# MIK32 register map
Vendor: Mikron; Series: MIK32; File version: 1.0
Registers are 32-bit, read-write, reset 0x0 unless marked. A register's access mark holds for its fields unless they carry their own. Offsets are from the block's base; [hi:lo] are bit positions; 'fields as' and 'values as' point back to an identical list.

## DMA — Прямой доступ к памяти
Base 0x00040000
0x00 CH1_DST — Регистр адреса назначения канала 1
  [31:0] DST — Адрес назначения. В режиме чтения текущего статуса (Current_valuе=1) возвращает последнюю переданную подзадачу контроллера канала. В случае ошибки записи содержит указатель на текущий адрес мастер-интерфейса
0x04 CH1_SRC — Регистр адреса источника канала 1
  [31:0] SCR — Адрес источника В режиме чтения текущего статуса (Current_valuе=1) возвращает текущую подзадачу контроллера канала. Указатель на адрес блока, который обрабатывается вычисляется как: Current_ch_read_task - 2^READ_BURST_SIZE В случае ошибки записи содержит указатель на текущий адрес мастер-интерфейса, вернувшего HRESP=1
0x08 CH1_LEN — Регистр размера передаваемых данных канала 1
  [31:0] LEN — Количество байт пересылки рассчитывается как LEN +1 В режиме чтения текущего статуса (Current_valuе=1) возвращает счётчик байт подзадач контроллера. Счётчик байт подзадач обновляется только по подзадачам записи. Кол-во байт в блоках, которые удалось записать вычисляется как: If (state==write): LEN - 2^WRITE_BURST_SIZE If (state==read): Current byte len
0x0C CH1_CFG — Регистр управления и конфигурации канала 1
  [27] IRQ_EN — Разрешение формирования пре-рывания по завершении работы канала: 0 – прерывание не формируется; 1 – прерывание формируется
    0=Disable (Прерывание не формируется); 1=Enable (Прерывание формируется)
  [26] WRITE_ACK_EN — Разрешение работы логики с откликом для адресата назначения
    0=Disable (Запрещено); 1=Enable (Разрешено)
  [25] READ_ACK_EN — Разрешение работы логики с откликом для адресата источника
    0=Disable (Запрещено); 1=Enable (Разрешено)
  [24:21] WRITE_REQUEST — Выбор периферийной линии назначения
    0=USART_0 (Линия запросов от USART_0); 1=USART_1 (Линия запросов от USART_1); 2=Crypto (Линия запросов от крипто-блока); 3=SPI_0 (Линия запросов от SPI_0); 4=SPI_1 (Линия запросов от SPI_1); 5=I2C_0 (Линия запросов от I2C_0); 6=I2C_1 (Линия запросов от I2C_1); 7=SPIFI (Линия запросов от SPIFI); 8=Timer32_1 (Линия запросов от Timer32_1); 9=Timer32_2 (Линия запросов от Timer32_2); 10=DAC0 (Линия запросов от DAC0); 11=DAC1 (Линия запросов от DAC1); 12=Timer32_0 (Линия запросов от Timer32_0)
  [20:17] READ_REQUEST — Выбор периферийной линии источника
    values as WRITE_REQUEST
  [16:14] WRITE_BURST_SIZE — Количество байт в пакете. Определяется как 2^write_block_size. Должно быть кратно write_size.
  [13:11] READ_BURST_SIZE — Количество байт в пакете. Определяется как 2^read_block_size. Должно быть кратно read_size.
  [10:9] WRITE_SIZE — Разрядность адреса назначения. Должно быть кратно LEN
    0=Byte (Байт); 1=2Byte (Полуслово); 2=4Byte (Слово); 3=Reserved (Резерв)
  [8:7] READ_SIZE — Разрядность адреса источника. Должно быть кратно data_len
    values as WRITE_SIZE
  [5] READ_INCREMENT — Инкремент адреса источника
    0=No_increment (Нет инкремента); 1=Increment (Есть инкремент)
  [5] WRITE_INCREMENT — Инкремент адреса назначения
    values as READ_INCREMENT
  [4] WRITE_MODE — Режим адреса назначения
    0=Periphery (Принудительная остановка); 1=Memory (Инициализация работы канала)
  [3] READ_MODE — Режим адреса источника
    values as WRITE_MODE
  [2:1] PRIOR — Приоритет канала
    0=Low (Принудительная остановка); 1=Medium (Инициализация работы канала); 2=High (Инициализация работы канала); 3=Very_high (Инициализация работы канала)
  [0] ENABLE — Разрешение работы канала
    0=Stop (Принудительная остановка); 1=Start (Инициализация работы канала)
0x10 CH2_DST — Регистр адреса назначения канала 2
  [31:0] Dst — Адрес назначения. В режиме чтения текущего статуса (Current_valuе=1) возвращает последнюю переданную подзадачу контроллера канала. В случае ошибки записи содержит указатель на текущий адрес мастер-интерфейса
0x14 CH2_SRC — Регистр адреса источника канала 2
  [31:0] Src — Адрес источника В режиме чтения текущего статуса (Current_valuе=1) возвращает текущую подзадачу контроллера канала. Указатель на адрес блока, который обрабатывается вычисляется как: Current_ch_read_task - 2^READ_BURST_SIZE В случае ошибки записи содержит указатель на текущий адрес мастер-интерфейса, вернувшего HRESP=1
0x18 CH2_LEN — Регистр размера передаваемых данных канала 2
  fields as CH1_LEN
0x1C CH2_CFG — Регистр управления и конфигурации канала 2
  [27] IRQ_EN — Разрешение формирования пре-рывания по завершении работы канала: 0 – прерывание не формируется; 1 – прерывание формируется
    values as CH1_CFG.IRQ_EN
  [26] WRITE_ACK_EN — Разрешение работы логики с откликом для адресата назначения
    0=Disable (Запрещено); 1=Enable (Разрешено)
  [25] READ_ACK_EN — Разрешение работы логики с откликом для адресата источника
    0=Disable (Запрещено); 1=Enable (Разрешено)
  [24:21] WRITE_REQUEST — Выбор периферийной линии назначения
    values as CH1_CFG.WRITE_REQUEST
  [20:17] READ_REQUEST — Выбор периферийной линии источника
    values as CH1_CFG.WRITE_REQUEST
  [16:14] WRITE_BURST_SIZE — Количество байт в пакете. Определяется как 2^write_block_size. Должно быть кратно write_size.
  [13:11] READ_BURST_SIZE — Количество байт в пакете. Определяется как 2^read_block_size. Должно быть кратно read_size.
  [10:9] WRITE_SIZE — Разрядность адреса назначения. Должно быть кратно LEN
    0=Byte (Байт); 1=2Byte (Полуслово); 2=4Byte (Слово)
  [8:7] READ_SIZE — Разрядность адреса источника. Должно быть кратно data_len
    0=Byte (Байт); 1=2Byte (Полуслово); 2=4Byte (Слово)
  [5] READ_INCREMENT — Инкремент адреса источника
    values as CH1_CFG.READ_INCREMENT
  [5] WRITE_INCREMENT — Инкремент адреса назначения
    values as CH1_CFG.READ_INCREMENT
  [4] WRITE_MODE — Режим адреса назначения
    values as CH1_CFG.WRITE_MODE
  [3] READ_MODE — Режим адреса источника
    values as CH1_CFG.WRITE_MODE
  [2:1] PRIOR — Приоритет канала
    values as CH1_CFG.PRIOR
  [0] ENABLE — Разрешение работы канала
    values as CH1_CFG.ENABLE
0x20 CH3_DST — Регистр адреса назначения канала 3
  fields as CH2_DST
0x24 CH3_SRC — Регистр адреса источника канала 3
  fields as CH2_SRC
0x28 CH3_LEN — Регистр размера передаваемых данных канала 3
  fields as CH1_LEN
0x2C CH3_CFG — Регистр управления и конфигурации канала 3
  fields as CH2_CFG
0x30 CH4_DST — Регистр адреса назначения канала 4
  fields as CH2_DST
0x34 CH4_SRC — Регистр адреса источника канала 4
  fields as CH2_SRC
0x38 CH4_LEN — Регистр размера передаваемых данных канала 4
  fields as CH1_LEN
0x3C CH4_CFG — Регистр управления и конфигурации канала 4
  [27] IRQ_EN — Разрешение формирования прерывания по завершении работы канала: 0 – прерывание не формируется; 1 – прерывание формируется
    values as CH1_CFG.IRQ_EN
  [26] WRITE_ACK_EN — Разрешение работы логики с откликом для адресата назначения
    0=Disable (Запрещено); 1=Enable (Разрешено)
  [25] READ_ACK_EN — Разрешение работы логики с откликом для адресата источника
    0=Disable (Запрещено); 1=Enable (Разрешено)
  [24:21] WRITE_REQUEST — Выбор периферийной линии назначения
    values as CH1_CFG.WRITE_REQUEST
  [20:17] READ_REQUEST — Выбор периферийной линии источника
    values as CH1_CFG.WRITE_REQUEST
  [16:14] WRITE_BURST_SIZE — Количество байт в пакете. Определяется как 2^write_block_size. Должно быть кратно write_size.
  [13:11] READ_BURST_SIZE — Количество байт в пакете. Определяется как 2^read_block_size. Должно быть кратно read_size.
  [10:9] WRITE_SIZE — Разрядность адреса назначения. Должно быть кратно LEN
    0=Byte (Байт); 1=2Byte (Полуслово); 2=4Byte (Слово)
  [8:7] READ_SIZE — Разрядность адреса источника. Должно быть кратно data_len
    0=Byte (Байт); 1=2Byte (Полуслово); 2=4Byte (Слово)
  [5] READ_INCREMENT — Инкремент адреса источника
    values as CH1_CFG.READ_INCREMENT
  [5] WRITE_INCREMENT — Инкремент адреса назначения
    values as CH1_CFG.READ_INCREMENT
  [4] WRITE_MODE — Режим адреса назначения
    values as CH1_CFG.WRITE_MODE
  [3] READ_MODE — Режим адреса источника
    values as CH1_CFG.WRITE_MODE
  [2:1] PRIOR — Приоритет канала
    values as CH1_CFG.PRIOR
  [0] ENABLE — Разрешение работы канала
    values as CH1_CFG.ENABLE
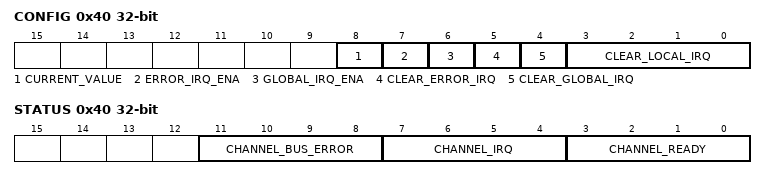
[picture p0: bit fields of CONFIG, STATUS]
0x40 CONFIG wo — Регистр прерываний и настройки контроллера при записи
  [8] CURRENT_VALUE — Разрешение чтения текущего статуса канала
    0=Disable (Разрешено (текущие значения)); 1=Enable (Запрещено (значения при настройке))
  [7] ERROR_IRQ_ENA — Разрешение формирования прерывания при ошибке
    0=Disable (Прерывание запрещено); 1=Enable (Прерывание разрешено)
  [6] GLOBAL_IRQ_ENA — Разрешение формирования глобального прерывания
    values as ERROR_IRQ_ENA
  [5] CLEAR_ERROR_IRQ — Очистка прерывания ошибки: «1» – снятие запроса на прерывание
    1=Reset (снятие запроса на прерывание)
  [4] CLEAR_GLOBAL_IRQ — Очистка глобального прерывания: «1» – снятие запроса на прерывание
    1=Reset (снятие запроса на прерывание)
  [3:0] CLEAR_LOCAL_IRQ — Очистка локального прерывания
    1=Reset (снятие запроса на прерывание)
0x40 STATUS ro — Регистр прерываний и настройки контроллера при чтении
  [11:8] CHANNEL_BUS_ERROR — Статус прерываний. Примечание – При передаче каналу нового задания, значения CHANNEL_BUS_ERROR сбрасываются в 0.
    1=Error (есть ошибка); 0=No_errror (нет ошибки)
  [7:4] CHANNEL_IRQ — Статус прерываний
    1=Interrupt (есть прерывания); 0=Uninterrupt (нет прерываний)
  [3:0] CHANNEL_READY — Статус состояния каналов: В режиме чтения текущего статуса (Current_valuе=1) возвращает: [0] - состояния ошибки при чтении (0 – ошибки не было; 1 – была зафиксирована ошибка шины при чтении) [1] - состояния ошибки при записи (0 – ошибки не было; 1 – была зафиксирована ошибка шины при записи) [3:2] состояния статуса контроллера канала (2’b01 – канал в состоянии чтения; 2’b10 – канала в состоянии записи)
    0=Busy (канал занят); 1=Ready (готов к работе)

## Notices in the file
MIT License
Copyright (c) 2024 Лаборатория системных разработок, Mikron
Permission is hereby granted, free of charge, to any person obtaining a copy
of this software and associated documentation files (the "Software"), to deal
in the Software without restriction, including without limitation the rights
to use, copy, modify, merge, publish, distribute, sublicense, and/or sell
copies of the Software, and to permit persons to whom the Software is
furnished to do so, subject to the following conditions:
The above copyright notice and this permission notice shall be included in all
copies or substantial portions of the Software.
THE SOFTWARE IS PROVIDED "AS IS", WITHOUT WARRANTY OF ANY KIND, EXPRESS OR
IMPLIED, INCLUDING BUT NOT LIMITED TO THE WARRANTIES OF MERCHANTABILITY,
FITNESS FOR A PARTICULAR PURPOSE AND NONINFRINGEMENT. IN NO EVENT SHALL THE
AUTHORS OR COPYRIGHT HOLDERS BE LIABLE FOR ANY CLAIM, DAMAGES OR OTHER
LIABILITY, WHETHER IN AN ACTION OF CONTRACT, TORT OR OTHERWISE, ARISING FROM,
OUT OF OR IN CONNECTION WITH THE SOFTWARE OR THE USE OR OTHER DEALINGS IN THE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
